# ETHSW register map
Registers are 32-bit, read-only, no defined reset value unless marked. A register's access mark holds for its fields unless they carry their own. Addresses are absolute; registers are grouped by the start of their names; [hi:lo] are bit positions; {n}, {i} and the like mark numbered series.

## TOTAL
0x44050300 TOTAL_DISC
0x44050304 TOTAL_BYT_DISC
0x44050308 TOTAL_FRM
0x4405030C TOTAL_BYT_FRM

## IDISC
{0x44050314+0x10*i} IDISC_VLAN{i} (i=0..4)
{0x44050318+0x10*i} IDISC_UNTAGGED{i} (i=0..4)
{0x4405031C+0x10*i} IDISC_BLOCKED{i} (i=0..4)

## LK
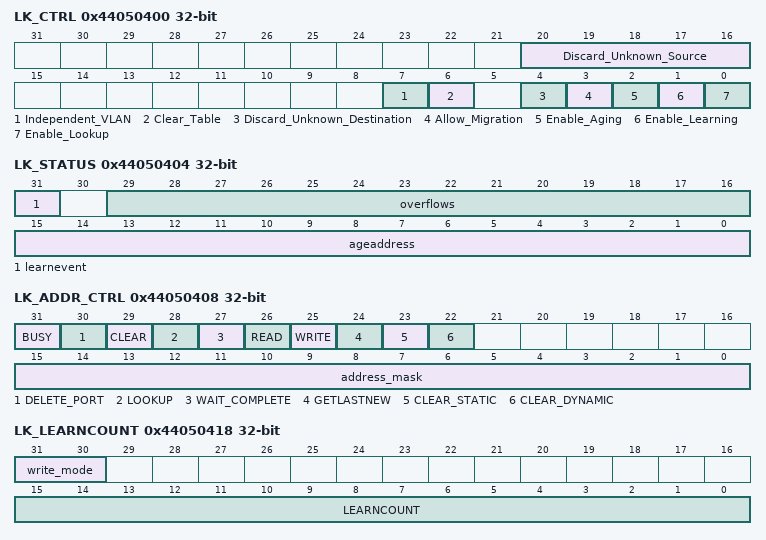
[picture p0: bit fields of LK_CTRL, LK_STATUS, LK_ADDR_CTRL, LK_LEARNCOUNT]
0x44050400 LK_CTRL access not given
  [20:16] Discard_Unknown_Source, [7] Independent_VLAN, [6] Clear_Table, [4] Discard_Unknown_Destination, [3] Allow_Migration, [2] Enable_Aging, [1] Enable_Learning, [0] Enable_Lookup
0x44050404 LK_STATUS access not given
  [31] learnevent, [29:16] overflows, [15:0] ageaddress
0x44050408 LK_ADDR_CTRL access not given
  [31] BUSY, [30] DELETE_PORT, [29] CLEAR, [28] LOOKUP, [27] WAIT_COMPLETE, [26] READ, [25] WRITE, [24] GETLASTNEW, [23] CLEAR_STATIC, [22] CLEAR_DYNAMIC, [15:0] address_mask
0x4405040C LK_DATA_LO access not given
  [31:0] MEMDATA
0x44050410 LK_DATA_HI access not given
  [31:0] MEMDATA
0x44050414 LK_DATA_HI2 access not given
  [4:0] MEMDATA
0x44050418 LK_LEARNCOUNT access not given
  [31:30] write_mode, [15:0] LEARNCOUNT
0x4405041C LK_AGETIME access not given
  [23:0] LK_AGETIME

## PORT0
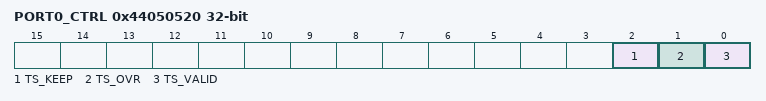
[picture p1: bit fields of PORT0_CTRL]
0x44050520 PORT0_CTRL access not given
  [2] TS_KEEP, [1] TS_OVR, [0] TS_VALID
0x44050524 PORT0_TIME

## PORT1
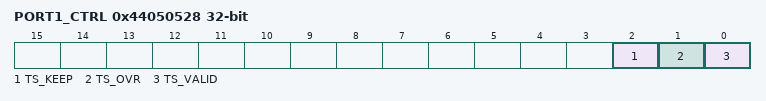
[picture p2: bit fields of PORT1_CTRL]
0x44050528 PORT1_CTRL access not given
  [2] TS_KEEP, [1] TS_OVR, [0] TS_VALID
0x4405052C PORT1_TIME

## PORT2
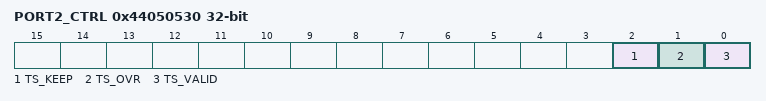
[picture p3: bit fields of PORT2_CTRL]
0x44050530 PORT2_CTRL access not given
  [2] TS_KEEP, [1] TS_OVR, [0] TS_VALID
0x44050534 PORT2_TIME

## PORT3
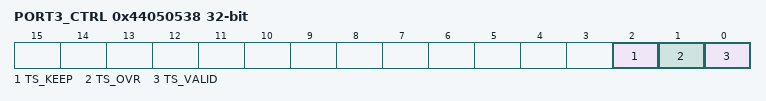
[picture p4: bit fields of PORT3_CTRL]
0x44050538 PORT3_CTRL access not given
  [2] TS_KEEP, [1] TS_OVR, [0] TS_VALID
0x4405053C PORT3_TIME

## INT
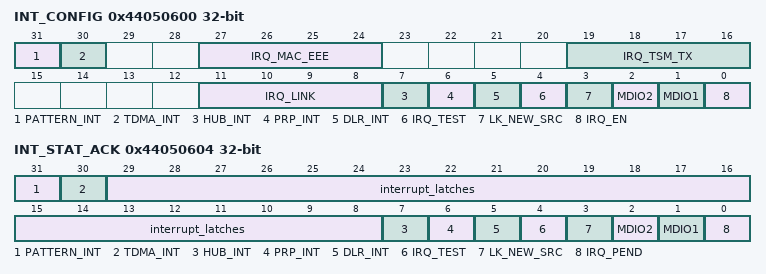
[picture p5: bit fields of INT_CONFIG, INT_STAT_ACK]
0x44050600 INT_CONFIG access not given
  [31] PATTERN_INT, [30] TDMA_INT, [27:24] IRQ_MAC_EEE, [19:16] IRQ_TSM_TX, [11:8] IRQ_LINK, [7] HUB_INT, [6] PRP_INT, [5] DLR_INT, [4] IRQ_TEST, [3] LK_NEW_SRC, [2] MDIO2, [1] MDIO1, [0] IRQ_EN
0x44050604 INT_STAT_ACK access not given
  [31] PATTERN_INT, [30] TDMA_INT, [29:8] interrupt_latches, [7] HUB_INT, [6] PRP_INT, [5] DLR_INT, [4] IRQ_TEST, [3] LK_NEW_SRC, [2] MDIO2, [1] MDIO1, [0] IRQ_PEND

## MDIO
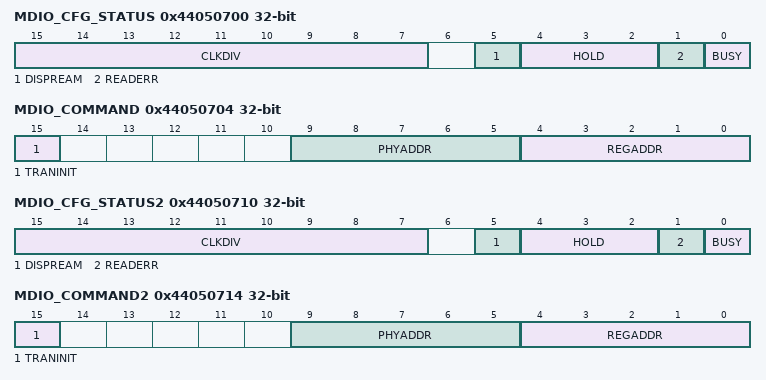
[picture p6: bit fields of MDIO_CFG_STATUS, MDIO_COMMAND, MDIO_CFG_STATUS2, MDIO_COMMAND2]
0x44050700 MDIO_CFG_STATUS access not given
  [15:7] CLKDIV, [5] DISPREAM, [4:2] HOLD, [1] READERR, [0] BUSY
0x44050704 MDIO_COMMAND access not given
  [15] TRANINIT, [9:5] PHYADDR, [4:0] REGADDR
0x44050708 MDIO_DATA access not given
  [15:0] MDIO_DATA
0x44050710 MDIO_CFG_STATUS2 access not given
  [15:7] CLKDIV, [5] DISPREAM, [4:2] HOLD, [1] READERR, [0] BUSY
0x44050714 MDIO_COMMAND2 access not given
  [15] TRANINIT, [9:5] PHYADDR, [4:0] REGADDR
0x44050718 MDIO_DATA2 access not given
  [15:0] MDIO_DATA

## REV
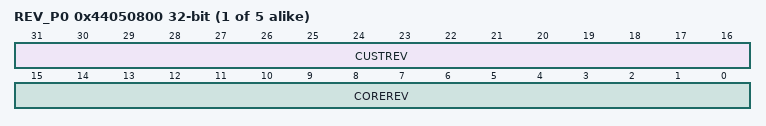
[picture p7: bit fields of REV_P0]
{0x44050800+0x400*i} REV_P{i} (i=0..4)
  [31:16] CUSTREV, [15:0] COREREV

## COMMAND
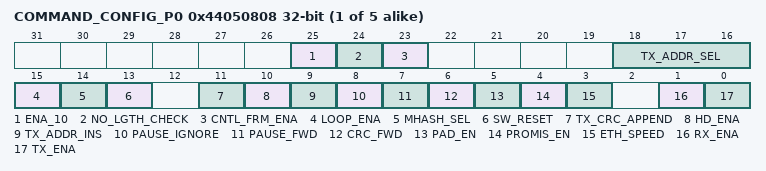
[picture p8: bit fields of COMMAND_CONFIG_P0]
{0x44050808+0x400*i} COMMAND_CONFIG_P{i} access not given (i=0..4)
  [25] ENA_10, [24] NO_LGTH_CHECK, [23] CNTL_FRM_ENA, [18:16] TX_ADDR_SEL, [15] LOOP_ENA, [14] MHASH_SEL, [13] SW_RESET, [11] TX_CRC_APPEND, [10] HD_ENA, [9] TX_ADDR_INS, [8] PAUSE_IGNORE, [7] PAUSE_FWD, [6] CRC_FWD, [5] PAD_EN, [4] PROMIS_EN, [3] ETH_SPEED, [1] RX_ENA, [0] TX_ENA

## MAC
{0x4405080C+0x400*i} MAC_ADDR_0_P{i} access not given (i=0..3)
  [31:0] MAC_ADDR
{0x44050810+0x400*i} MAC_ADDR_1_P{i} access not given (i=0..3)
  [15:0] MAC_ADDR

## FRM
{0x44050814+0x400*i} FRM_LENGTH_P{i} access not given (i=0..4)
  [13:0] FRM_LENGTH

## PAUSE
{0x44050818+0x400*i} PAUSE_QUANT_P{i} access not given (i=0..4)
  [15:0] PAUSE_QUANT
